AUTOSAR XML (schema 4-0-3)
standard types defined: uint8, Boolean, UInt16, UInt32, UInt8
package /AUTOSAR_Platform/DataConstrs
  range DC_Boolean: raw 0..1
  range DC_UInt16: raw 0..65535
  range DC_UInt8: raw 0..255
package /PATAC/Facility/DataTypes/Implementation
  compu method COMPU_Boolean: 0=FALSE, 1=TRUE
  unit NoUnit: factor-si-to-unit=1, offset-si-to-unit=0
package /PATAC/MSM/ComponentTypes
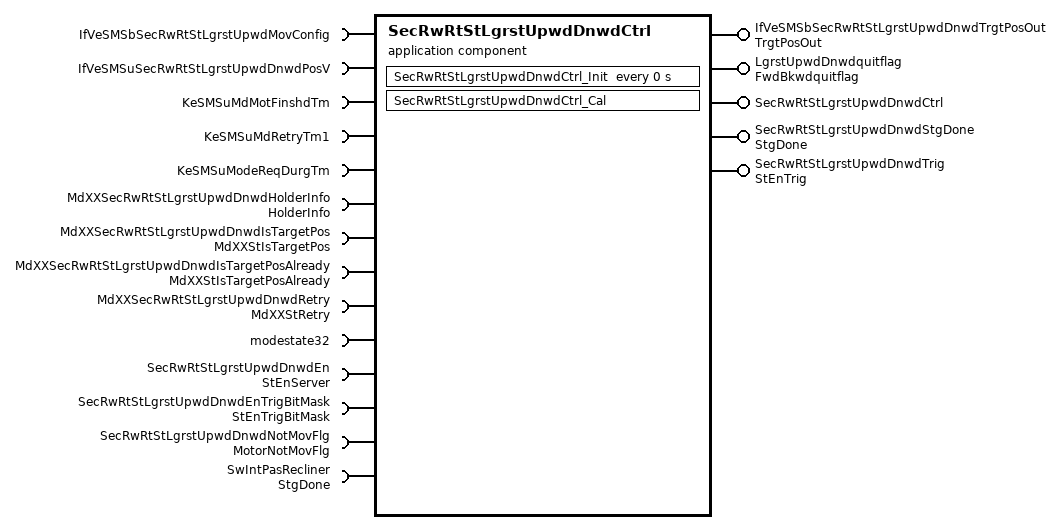
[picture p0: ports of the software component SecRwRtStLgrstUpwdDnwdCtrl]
  application sw component type SecRwRtStLgrstUpwdDnwdCtrl
    5 x provide port:
      IfVeSMSbSecRwRtStLgrstUpwdDnwdTrgtPosOut: nonqueued-sender-com-spec{data-element=TrgtPosOut/Val, init-value=0}, provided-interface=TrgtPosOut
      LgrstUpwdDnwdquitflag: nonqueued-sender-com-spec{data-element=FwdBkwdquitflag/Val, init-value=0}, provided-interface=FwdBkwdquitflag
      SecRwRtStLgrstUpwdDnwdCtrl: server-com-spec{operation=Cal, queue-length=1}, provided-interface=SecRwRtStLgrstUpwdDnwdCtrl
      SecRwRtStLgrstUpwdDnwdStgDone: nonqueued-sender-com-spec{data-element=StgDone/Val, init-value=0}, provided-interface=StgDone
      SecRwRtStLgrstUpwdDnwdTrig: nonqueued-sender-com-spec{data-element=StEnTrig/Val, init-value=0}, provided-interface=StEnTrig
    14 x require port:
      IfVeSMSbSecRwRtStLgrstUpwdMovConfig: nonqueued-receiver-com-spec{data-element=IfVeSMSbSecRwRtStLgrstUpwdMovConfig/Val, filter=data-filter-type=ALWAYS, init-value=0}, required-interface=IfVeSMSbSecRwRtStLgrstUpwdMovConfig
      IfVeSMSuSecRwRtStLgrstUpwdDnwdPosV: nonqueued-receiver-com-spec{data-element=IfVeSMSuSecRwRtStLgrstUpwdDnwdPosV/Val, filter=data-filter-type=ALWAYS, init-value=0}, required-interface=IfVeSMSuSecRwRtStLgrstUpwdDnwdPosV
      KeSMSuMdMotFinshdTm: parameter-require-com-spec{init-value=0, parameter=KeSMSuMdMotFinshdTm/Val}, required-interface=KeSMSuMdMotFinshdTm
      KeSMSuMdRetryTm1: parameter-require-com-spec{init-value=0, parameter=KeSMSuMdRetryTm1/Val}, required-interface=KeSMSuMdRetryTm1
      KeSMSuModeReqDurgTm: parameter-require-com-spec{init-value=0, parameter=KeSMSuModeReqDurgTm/Val}, required-interface=KeSMSuModeReqDurgTm
      MdXXSecRwRtStLgrstUpwdDnwdHolderInfo: nonqueued-receiver-com-spec{data-element=HolderInfo/Val, filter=data-filter-type=ALWAYS, init-value=0}, required-interface=HolderInfo
      MdXXSecRwRtStLgrstUpwdDnwdIsTargetPos: nonqueued-receiver-com-spec{data-element=MdXXStIsTargetPos/Val, filter=data-filter-type=ALWAYS, init-value=0}, required-interface=MdXXStIsTargetPos
      MdXXSecRwRtStLgrstUpwdDnwdIsTargetPosAlready: nonqueued-receiver-com-spec{data-element=MdXXStIsTargetPosAlready/Val, filter=data-filter-type=ALWAYS, init-value=0}, required-interface=MdXXStIsTargetPosAlready
      MdXXSecRwRtStLgrstUpwdDnwdRetry: nonqueued-receiver-com-spec{data-element=MdXXStRetry/Val, filter=data-filter-type=ALWAYS, init-value=0}, required-interface=MdXXStRetry
      modestate32: nonqueued-receiver-com-spec{data-element=modestate32/Val, filter=data-filter-type=ALWAYS, init-value=0}, required-interface=modestate32
      SecRwRtStLgrstUpwdDnwdEn: required-com-specs=[Clear, Get, Set], required-interface=StEnServer
      SecRwRtStLgrstUpwdDnwdEnTrigBitMask: nonqueued-receiver-com-spec{data-element=StEnTrigBitMask/Val, filter=data-filter-type=ALWAYS, init-value=0}, required-interface=StEnTrigBitMask
      SecRwRtStLgrstUpwdDnwdNotMovFlg: nonqueued-receiver-com-spec{data-element=MotorNotMovFlg/Val, filter=data-filter-type=ALWAYS, init-value=0}, required-interface=MotorNotMovFlg
      SwIntPasRecliner: nonqueued-receiver-com-spec{data-element=StgDone/Val, filter=data-filter-type=ALWAYS, init-value=0}, required-interface=StgDone
    behavior SecRwRtStLgrstUpwdDnwdCtrl_InternalBehavior
      operation invoked event OIT_SecRwRtStLgrstUpwdDnwdCtrl_Cal_SecRwRtStLgrstUpwdDnwdCtrl_Cal: start-on-event=SecRwRtStLgrstUpwdDnwdCtrl_Cal, operation=SecRwRtStLgrstUpwdDnwdCtrl.Cal
      timing event SecRwRtStLgrstUpwdDnwdCtrl_InitEvent: start-on-event=SecRwRtStLgrstUpwdDnwdCtrl_Init, period=0
      runnable SecRwRtStLgrstUpwdDnwdCtrl_Cal
        data-receive-point-by-arguments:
          10 x access:
            REC_IfVeSMSbSecRwRtStLgrstUpwdMovConfig_Val: accessed-variable=IfVeSMSbSecRwRtStLgrstUpwdMovConfig.Val
            REC_IfVeSMSuSecRwRtStLgrstUpwdDnwdPosV_Val: accessed-variable=IfVeSMSuSecRwRtStLgrstUpwdDnwdPosV.Val
            REC_MdXXSecRwRtStLgrstUpwdDnwdHolderInfo_Val: accessed-variable=MdXXSecRwRtStLgrstUpwdDnwdHolderInfo.Val
            REC_MdXXSecRwRtStLgrstUpwdDnwdIsTargetPos_Val: accessed-variable=MdXXSecRwRtStLgrstUpwdDnwdIsTargetPos.Val
            REC_MdXXSecRwRtStLgrstUpwdDnwdIsTargetPosAlready_Val: accessed-variable=MdXXSecRwRtStLgrstUpwdDnwdIsTargetPosAlready.Val
            REC_MdXXSecRwRtStLgrstUpwdDnwdRetry_Val: accessed-variable=MdXXSecRwRtStLgrstUpwdDnwdRetry.Val
            REC_modestate32_Val: accessed-variable=modestate32.Val
            REC_SecRwRtStLgrstUpwdDnwdEnTrigBitMask_Val: accessed-variable=SecRwRtStLgrstUpwdDnwdEnTrigBitMask.Val
            REC_SecRwRtStLgrstUpwdDnwdNotMovFlg_Val: accessed-variable=SecRwRtStLgrstUpwdDnwdNotMovFlg.Val
            REC_SwIntPasRecliner_Val: accessed-variable=SwIntPasRecliner.Val
        data-send-points:
          4 x access:
            SEND_IfVeSMSbSecRwRtStLgrstUpwdDnwdTrgtPosOut_Val: accessed-variable=IfVeSMSbSecRwRtStLgrstUpwdDnwdTrgtPosOut.Val
            SEND_LgrstUpwdDnwdquitflag_Val: accessed-variable=LgrstUpwdDnwdquitflag.Val
            SEND_SecRwRtStLgrstUpwdDnwdStgDone_Val: accessed-variable=SecRwRtStLgrstUpwdDnwdStgDone.Val
            SEND_SecRwRtStLgrstUpwdDnwdTrig_Val: accessed-variable=SecRwRtStLgrstUpwdDnwdTrig.Val
        parameter access PA_KeSMSuMdMotFinshdTm_Val: accessed-parameter=KeSMSuMdMotFinshdTm.Val
        parameter access PA_KeSMSuMdRetryTm1_Val: accessed-parameter=KeSMSuMdRetryTm1.Val
        parameter access PA_KeSMSuModeReqDurgTm_Val: accessed-parameter=KeSMSuModeReqDurgTm.Val
        sync call SC_SecRwRtStLgrstUpwdDnwdEn_Get: operation=SecRwRtStLgrstUpwdDnwdEn.Get, timeout=0
      runnable SecRwRtStLgrstUpwdDnwdCtrl_Init
        parameter access PA_KeSMSuMdMotFinshdTm_Val: accessed-parameter=KeSMSuMdMotFinshdTm.Val
        parameter access PA_KeSMSuMdRetryTm1_Val: accessed-parameter=KeSMSuMdRetryTm1.Val
        parameter access PA_KeSMSuModeReqDurgTm_Val: accessed-parameter=KeSMSuModeReqDurgTm.Val
  swc implementation SecRwRtStLgrstUpwdDnwdCtrl_Implementation: behavior=SecRwRtStLgrstUpwdDnwdCtrl_InternalBehavior
    code-descriptors:
      code Default: artifact-descriptors=autosar-engineering-object={short-label=Default, category=SWSRC}
package /PATAC/MSM/ModeAdjust/CalPortInterface
  parameter interface KeSMSuMdMotFinshdTm
    parameter data prototype Val: sw-calibration-access=READ-WRITE, type=UInt16
  parameter interface KeSMSuModeReqDurgTm
    parameter data prototype Val: sw-calibration-access=READ-WRITE, type=UInt16
package /PATAC/MSM/ModeAdjust/Interfaces
  sender receiver interface IfVeSMSuSecRwRtStLgrstUpwdDnwdPosV: invalidation-policy{data-element=IfVeSMSuSecRwRtStLgrstUpwdDnwdPosV/Val, handle-invalid=DONT-INVALIDATE}
    data Val: type=Boolean
package /PATAC/MSM/ModeAdjust/PortInterface
  client server interface SecRwRtStLgrstUpwdDnwdCtrl
    operation Cal
  client server interface StEnServer
    operation Clear
      arg data: type=UInt8, direction=IN, server-argument-impl-policy=USE-ARGUMENT-TYPE
    operation Get
      arg data: type=UInt32, direction=OUT, server-argument-impl-policy=USE-ARGUMENT-TYPE
    operation Set
      arg data: type=UInt8, direction=IN, server-argument-impl-policy=USE-ARGUMENT-TYPE
  11 x sender receiver interface:
    FwdBkwdquitflag: invalidation-policy{data-element=FwdBkwdquitflag/Val, handle-invalid=DONT-INVALIDATE}
      data Val: type=Boolean
    HolderInfo: invalidation-policy{data-element=HolderInfo/Val, handle-invalid=DONT-INVALIDATE}
      data Val: type=UInt32
    MdXXStIsTargetPos: invalidation-policy{data-element=MdXXStIsTargetPos/Val, handle-invalid=DONT-INVALIDATE}
      data Val: type=UInt32
    MdXXStIsTargetPosAlready: invalidation-policy{data-element=MdXXStIsTargetPosAlready/Val, handle-invalid=DONT-INVALIDATE}
      data Val: type=UInt32
    MdXXStRetry: invalidation-policy{data-element=MdXXStRetry/Val, handle-invalid=DONT-INVALIDATE}
      data Val: type=UInt32
    modestate32: invalidation-policy{data-element=modestate32/Val, handle-invalid=DONT-INVALIDATE}
      data Val: type=UInt32
    MotorNotMovFlg: invalidation-policy{data-element=MotorNotMovFlg/Val, handle-invalid=DONT-INVALIDATE}
      data Val: type=Boolean
    StEnTrig: invalidation-policy{data-element=StEnTrig/Val, handle-invalid=DONT-INVALIDATE}
      data Val: type=Boolean
    StEnTrigBitMask: invalidation-policy{data-element=StEnTrigBitMask/Val, handle-invalid=DONT-INVALIDATE}
      data Val: type=UInt32
    StgDone: invalidation-policy{data-element=StgDone/Val, handle-invalid=DONT-INVALIDATE}
      data Val: type=Boolean
    TrgtPosOut: invalidation-policy{data-element=TrgtPosOut/Val, handle-invalid=DONT-INVALIDATE}
      data Val: type=Boolean
package /PATAC/MSM/PortInterfaces
  parameter interface KeSMSuMdRetryTm1
    parameter data prototype Val: sw-calibration-access=READ-WRITE, type=UInt8
  sender receiver interface IfVeSMSbSecRwRtStLgrstUpwdMovConfig: invalidation-policy{data-element=IfVeSMSbSecRwRtStLgrstUpwdMovConfig/Val, handle-invalid=DONT-INVALIDATE}
    data Val: type=Boolean
